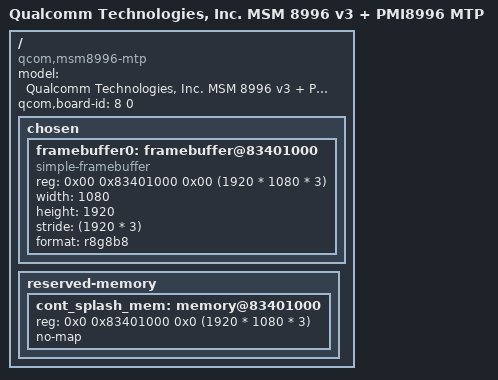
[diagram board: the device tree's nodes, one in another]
/* Copyright (c) 2015, The Linux Foundation. All rights reserved.
 *
 * This program is free software; you can redistribute it and/or modify
 * it under the terms of the GNU General Public License version 2 and
 * only version 2 as published by the Free Software Foundation.
 *
 * This program is distributed in the hope that it will be useful,
 * but WITHOUT ANY WARRANTY; without even the implied warranty of
 * MERCHANTABILITY or FITNESS FOR A PARTICULAR PURPOSE.  See the
 * GNU General Public License for more details.
 */


/dts-v1/;

#include "msm8996-v3.dtsi"
#include "msm-pmi8996.dtsi"
#include "msm8996-mtp.dtsi"

/ {
	model = "Qualcomm Technologies, Inc. MSM 8996 v3 + PMI8996 MTP";
	compatible = "qcom,msm8996-mtp", "qcom,msm8996", "qcom,mtp";
	qcom,board-id = <8 0>;

	chosen {
		#address-cells = <2>;
		#size-cells = <2>;
		ranges;

		framebuffer0: framebuffer@83401000 {
			compatible = "simple-framebuffer";
			reg = <0x00 0x83401000 0x00 (1920 * 1080 * 3)>;
			width = <1080>;
			height = <1920>;
			stride = <(1920 * 3)>;
			format = "r8g8b8";
		};
	};

	reserved-memory {
		cont_splash_mem: memory@83401000 {
			reg = <0x0 0x83401000 0x0 (1920 * 1080 * 3)>;
			no-map;
		};
	};
};

#include "zuk/z2_plus-base.dtsi"
